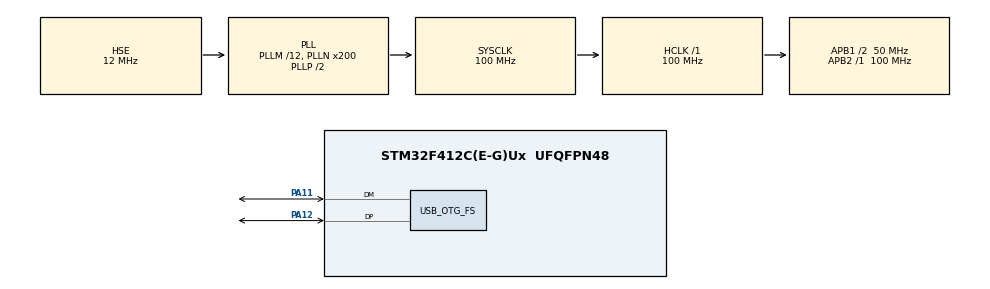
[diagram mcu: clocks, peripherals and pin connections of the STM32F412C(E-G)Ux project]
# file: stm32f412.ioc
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Mcu.Family=STM32F4
Mcu.Name=STM32F412C(E-G)Ux
Mcu.Package=UFQFPN48
NVIC.OTG_FS_IRQn=true\:0\:0\:false\:false\:true\:true\:true
NVIC.PriorityGroup=NVIC_PRIORITYGROUP_1
PA11.Mode=Device_Only
PA11.Signal=USB_OTG_FS_DM
PA12.Mode=Device_Only
PA12.Signal=USB_OTG_FS_DP
PA13.Mode=Trace_Asynchronous_SW
PA13.Signal=SYS_JTMS-SWDIO
PA14.Mode=Trace_Asynchronous_SW
PA14.Signal=SYS_JTCK-SWCLK
PB3.Mode=Trace_Asynchronous_SW
PB3.Signal=SYS_JTDO-SWO
PH0\ -\ OSC_IN.Mode=HSE-External-Oscillator
PH0\ -\ OSC_IN.Signal=RCC_OSC_IN
PH1\ -\ OSC_OUT.Mode=HSE-External-Oscillator
PH1\ -\ OSC_OUT.Signal=RCC_OSC_OUT
ProjectManager.HeapSize=0x200
ProjectManager.StackSize=0xC00
ProjectManager.TargetToolchain=MDK-ARM V5
RCC.AHBFreq_Value=100000000
RCC.APB1CLKDivider=RCC_HCLK_DIV2
RCC.APB1Freq_Value=50000000
RCC.APB1TimFreq_Value=100000000
RCC.APB2Freq_Value=100000000
RCC.APB2TimFreq_Value=100000000
RCC.CortexFreq_Value=100000000
RCC.HCLKFreq_Value=100000000
RCC.HSE_VALUE=12000000
RCC.PLLI2SM=12
RCC.PLLI2SQ=4
RCC.PLLM=12
RCC.PLLN=200
RCC.PLLSourceVirtual=RCC_PLLSOURCE_HSE
RCC.SYSCLKFreq_VALUE=100000000
RCC.SYSCLKSource=RCC_SYSCLKSOURCE_PLLCLK
RCC.USBCLockSelection=RCC_CLK48CLKSOURCE_PLLI2SQ
RCC.USBFreq_Value=48000000
RCC.VCOOutputFreq_Value=200000000
USB_OTG_FS.VirtualMode=Device_Only
board=custom

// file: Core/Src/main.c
/* USER CODE BEGIN Header */
/**
  ******************************************************************************
  * @file           : main.c
  * @brief          : Main program body
  ******************************************************************************
  * @attention
  *
  * <h2><center>&copy; Copyright (c) 2021 STMicroelectronics.
  * All rights reserved.</center></h2>
  *
  * This software component is licensed by ST under BSD 3-Clause license,
  * the "License"; You may not use this file except in compliance with the
  * License. You may obtain a copy of the License at:
  *                        opensource.org/licenses/BSD-3-Clause
  *
  ******************************************************************************
  */
/* USER CODE END Header */
#include "main.h"

PCD_HandleTypeDef hpcd_USB_OTG_FS;

void SystemClock_Config(void);
static void MX_GPIO_Init(void);
static void MX_USB_OTG_FS_PCD_Init(void);

/* USER CODE BEGIN 0 */
__WEAK void StartUSB()
{
}
/* USER CODE END 0 */

int main(void)
{

  /* MCU Configuration--------------------------------------------------------*/

  /* Reset of all peripherals, Initializes the Flash interface and the Systick. */
  HAL_Init();

  /* Configure the system clock */
  SystemClock_Config();

  /* Initialize all configured peripherals */
  MX_GPIO_Init();
  MX_USB_OTG_FS_PCD_Init();
  /* USER CODE BEGIN 2 */
	StartUSB();
  /* USER CODE END 2 */

  /* Infinite loop */
  while (1)
  {

  }
}

void SystemClock_Config(void)
{
  RCC_OscInitTypeDef RCC_OscInitStruct = {0};
  RCC_ClkInitTypeDef RCC_ClkInitStruct = {0};
  RCC_PeriphCLKInitTypeDef PeriphClkInitStruct = {0};

  /** Configure the main internal regulator output voltage
  */
  __HAL_RCC_PWR_CLK_ENABLE();
  __HAL_PWR_VOLTAGESCALING_CONFIG(PWR_REGULATOR_VOLTAGE_SCALE1);
  /** Initializes the RCC Oscillators according to the specified parameters
  * in the RCC_OscInitTypeDef structure.
  */
  RCC_OscInitStruct.OscillatorType = RCC_OSCILLATORTYPE_HSE;
  RCC_OscInitStruct.HSEState = RCC_HSE_ON;
  RCC_OscInitStruct.PLL.PLLState = RCC_PLL_ON;
  RCC_OscInitStruct.PLL.PLLSource = RCC_PLLSOURCE_HSE;
  RCC_OscInitStruct.PLL.PLLM = 12;
  RCC_OscInitStruct.PLL.PLLN = 200;
  RCC_OscInitStruct.PLL.PLLP = RCC_PLLP_DIV2;
  RCC_OscInitStruct.PLL.PLLQ = 2;
  RCC_OscInitStruct.PLL.PLLR = 2;
  if (HAL_RCC_OscConfig(&RCC_OscInitStruct) != HAL_OK)
  {
    Error_Handler();
  }
  /** Initializes the CPU, AHB and APB buses clocks
  */
  RCC_ClkInitStruct.ClockType = RCC_CLOCKTYPE_HCLK|RCC_CLOCKTYPE_SYSCLK
                              |RCC_CLOCKTYPE_PCLK1|RCC_CLOCKTYPE_PCLK2;
  RCC_ClkInitStruct.SYSCLKSource = RCC_SYSCLKSOURCE_PLLCLK;
  RCC_ClkInitStruct.AHBCLKDivider = RCC_SYSCLK_DIV1;
  RCC_ClkInitStruct.APB1CLKDivider = RCC_HCLK_DIV2;
  RCC_ClkInitStruct.APB2CLKDivider = RCC_HCLK_DIV1;

  if (HAL_RCC_ClockConfig(&RCC_ClkInitStruct, FLASH_LATENCY_3) != HAL_OK)
  {
    Error_Handler();
  }
  PeriphClkInitStruct.PeriphClockSelection = RCC_PERIPHCLK_CLK48;
  PeriphClkInitStruct.PLLI2S.PLLI2SN = 192;
  PeriphClkInitStruct.PLLI2S.PLLI2SM = 12;
  PeriphClkInitStruct.PLLI2S.PLLI2SR = 2;
  PeriphClkInitStruct.PLLI2S.PLLI2SQ = 4;
  PeriphClkInitStruct.Clk48ClockSelection = RCC_CLK48CLKSOURCE_PLLI2SQ;
  PeriphClkInitStruct.PLLI2SSelection = RCC_PLLI2SCLKSOURCE_PLLSRC;
  if (HAL_RCCEx_PeriphCLKConfig(&PeriphClkInitStruct) != HAL_OK)
  {
    Error_Handler();
  }
}

static void MX_USB_OTG_FS_PCD_Init(void)
{

  /* USER CODE BEGIN USB_OTG_FS_Init 0 */
#if	0
  /* USER CODE END USB_OTG_FS_Init 0 */

  hpcd_USB_OTG_FS.Instance = USB_OTG_FS;
  hpcd_USB_OTG_FS.Init.dev_endpoints = 6;
  hpcd_USB_OTG_FS.Init.speed = PCD_SPEED_FULL;
  hpcd_USB_OTG_FS.Init.dma_enable = DISABLE;
  hpcd_USB_OTG_FS.Init.phy_itface = PCD_PHY_EMBEDDED;
  hpcd_USB_OTG_FS.Init.Sof_enable = DISABLE;
  hpcd_USB_OTG_FS.Init.low_power_enable = DISABLE;
  hpcd_USB_OTG_FS.Init.lpm_enable = DISABLE;
  hpcd_USB_OTG_FS.Init.battery_charging_enable = DISABLE;
  hpcd_USB_OTG_FS.Init.vbus_sensing_enable = DISABLE;
  hpcd_USB_OTG_FS.Init.use_dedicated_ep1 = DISABLE;
  if (HAL_PCD_Init(&hpcd_USB_OTG_FS) != HAL_OK)
  {
    Error_Handler();
  }
  /* USER CODE BEGIN USB_OTG_FS_Init 2 */
#endif
  /* USER CODE END USB_OTG_FS_Init 2 */

}

static void MX_GPIO_Init(void)
{

  /* GPIO Ports Clock Enable */
  __HAL_RCC_GPIOH_CLK_ENABLE();
  __HAL_RCC_GPIOA_CLK_ENABLE();
  __HAL_RCC_GPIOB_CLK_ENABLE();

}

void Error_Handler(void)
{
  __disable_irq();
  while (1)
  {
  }
}

/************************ (C) COPYRIGHT STMicroelectronics *****END OF FILE****/
